AUTOSAR XML (schema 4-2-2)
package /Nexteer/NvMProxy_swc/ComponentTypes
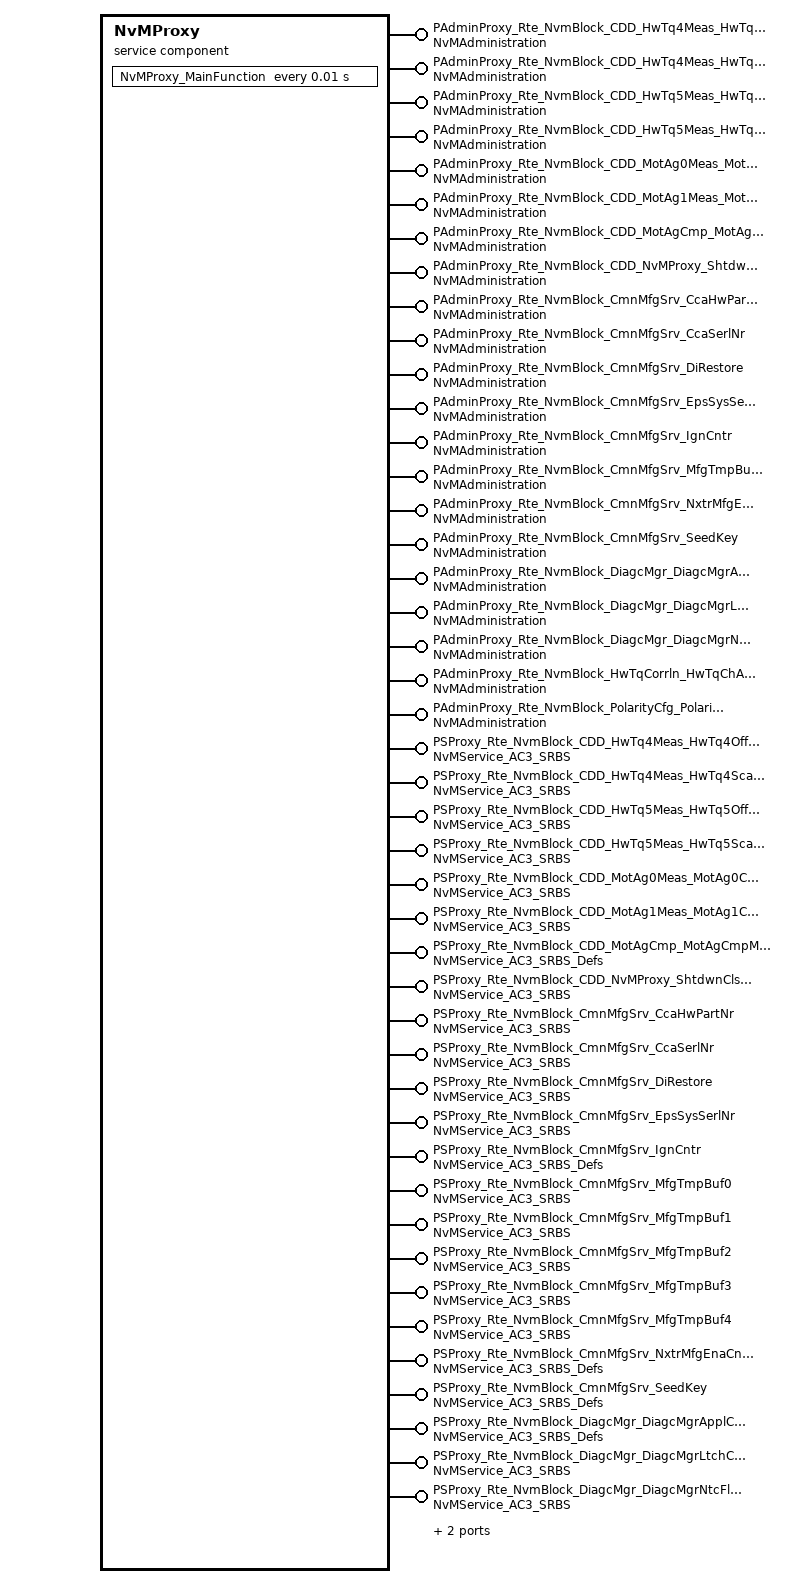
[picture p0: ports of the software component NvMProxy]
  service sw component type NvMProxy
    50 x provide port:
      PAdminProxy_Rte_NvmBlock_CDD_HwTq4Meas_HwTq4Offs_MirrorBlock: server-com-spec{operation=SetBlockProtection, queue-length=1}, provided-interface=NvMAdministration
      PAdminProxy_Rte_NvmBlock_CDD_HwTq4Meas_HwTq4Sca_MirrorBlock: server-com-spec{operation=SetBlockProtection, queue-length=1}, provided-interface=NvMAdministration
      PAdminProxy_Rte_NvmBlock_CDD_HwTq5Meas_HwTq5Offs_MirrorBlock: server-com-spec{operation=SetBlockProtection, queue-length=1}, provided-interface=NvMAdministration
      PAdminProxy_Rte_NvmBlock_CDD_HwTq5Meas_HwTq5Sca_MirrorBlock: server-com-spec{operation=SetBlockProtection, queue-length=1}, provided-interface=NvMAdministration
      PAdminProxy_Rte_NvmBlock_CDD_MotAg0Meas_MotAg0CoeffTbl: server-com-spec{operation=SetBlockProtection, queue-length=1}, provided-interface=NvMAdministration
      PAdminProxy_Rte_NvmBlock_CDD_MotAg1Meas_MotAg1CoeffTbl: server-com-spec{operation=SetBlockProtection, queue-length=1}, provided-interface=NvMAdministration
      PAdminProxy_Rte_NvmBlock_CDD_MotAgCmp_MotAgCmpMotAgBackEmf: server-com-spec{operation=SetBlockProtection, queue-length=1}, provided-interface=NvMAdministration
      PAdminProxy_Rte_NvmBlock_CDD_NvMProxy_ShtdwnClsChk: server-com-spec{operation=SetBlockProtection, queue-length=1}, provided-interface=NvMAdministration
      PAdminProxy_Rte_NvmBlock_CmnMfgSrv_CcaHwPartNr: server-com-spec{operation=SetBlockProtection, queue-length=1}, provided-interface=NvMAdministration
      PAdminProxy_Rte_NvmBlock_CmnMfgSrv_CcaSerlNr: server-com-spec{operation=SetBlockProtection, queue-length=1}, provided-interface=NvMAdministration
      PAdminProxy_Rte_NvmBlock_CmnMfgSrv_DiRestore: server-com-spec{operation=SetBlockProtection, queue-length=1}, provided-interface=NvMAdministration
      PAdminProxy_Rte_NvmBlock_CmnMfgSrv_EpsSysSerlNr: server-com-spec{operation=SetBlockProtection, queue-length=1}, provided-interface=NvMAdministration
      PAdminProxy_Rte_NvmBlock_CmnMfgSrv_IgnCntr: server-com-spec{operation=SetBlockProtection, queue-length=1}, provided-interface=NvMAdministration
      PAdminProxy_Rte_NvmBlock_CmnMfgSrv_MfgTmpBuf{0..4}: server-com-spec{operation=SetBlockProtection, queue-length=1}, provided-interface=NvMAdministration
      PAdminProxy_Rte_NvmBlock_CmnMfgSrv_NxtrMfgEnaCntr: server-com-spec{operation=SetBlockProtection, queue-length=1}, provided-interface=NvMAdministration
      PAdminProxy_Rte_NvmBlock_CmnMfgSrv_SeedKey: server-com-spec{operation=SetBlockProtection, queue-length=1}, provided-interface=NvMAdministration
      PAdminProxy_Rte_NvmBlock_DiagcMgr_DiagcMgrApplCrc: server-com-spec{operation=SetBlockProtection, queue-length=1}, provided-interface=NvMAdministration
      PAdminProxy_Rte_NvmBlock_DiagcMgr_DiagcMgrLtchCntrAry: server-com-spec{operation=SetBlockProtection, queue-length=1}, provided-interface=NvMAdministration
      PAdminProxy_Rte_NvmBlock_DiagcMgr_DiagcMgrNtcFltAry: server-com-spec{operation=SetBlockProtection, queue-length=1}, provided-interface=NvMAdministration
      PAdminProxy_Rte_NvmBlock_HwTqCorrln_HwTqChACmnModCmpLpFilSt: server-com-spec{operation=SetBlockProtection, queue-length=1}, provided-interface=NvMAdministration
      PAdminProxy_Rte_NvmBlock_PolarityCfg_PolarityCfgSaved: server-com-spec{operation=SetBlockProtection, queue-length=1}, provided-interface=NvMAdministration
      PSProxy_Rte_NvmBlock_CDD_HwTq4Meas_HwTq4Offs_MirrorBlock: provided-interface=NvMService_AC3_SRBS
        provided-com-specs:
          operation=EraseBlock, queue-length=1
          operation=GetErrorStatus, queue-length=1
          operation=InvalidateNvBlock, queue-length=1
          operation=ReadBlock, queue-length=1
          operation=SetRamBlockStatus, queue-length=1
          operation=WriteBlock, queue-length=1
      PSProxy_Rte_NvmBlock_CDD_HwTq4Meas_HwTq4Sca_MirrorBlock: provided-interface=NvMService_AC3_SRBS
        provided-com-specs:
          operation=EraseBlock, queue-length=1
          operation=GetErrorStatus, queue-length=1
          operation=InvalidateNvBlock, queue-length=1
          operation=ReadBlock, queue-length=1
          operation=SetRamBlockStatus, queue-length=1
          operation=WriteBlock, queue-length=1
      PSProxy_Rte_NvmBlock_CDD_HwTq5Meas_HwTq5Offs_MirrorBlock: provided-interface=NvMService_AC3_SRBS
        provided-com-specs:
          operation=EraseBlock, queue-length=1
          operation=GetErrorStatus, queue-length=1
          operation=InvalidateNvBlock, queue-length=1
          operation=ReadBlock, queue-length=1
          operation=SetRamBlockStatus, queue-length=1
          operation=WriteBlock, queue-length=1
      PSProxy_Rte_NvmBlock_CDD_HwTq5Meas_HwTq5Sca_MirrorBlock: provided-interface=NvMService_AC3_SRBS
        provided-com-specs:
          operation=EraseBlock, queue-length=1
          operation=GetErrorStatus, queue-length=1
          operation=InvalidateNvBlock, queue-length=1
          operation=ReadBlock, queue-length=1
          operation=SetRamBlockStatus, queue-length=1
          operation=WriteBlock, queue-length=1
      PSProxy_Rte_NvmBlock_CDD_MotAg0Meas_MotAg0CoeffTbl: provided-interface=NvMService_AC3_SRBS
        provided-com-specs:
          operation=EraseBlock, queue-length=1
          operation=GetErrorStatus, queue-length=1
          operation=InvalidateNvBlock, queue-length=1
          operation=ReadBlock, queue-length=1
          operation=SetRamBlockStatus, queue-length=1
          operation=WriteBlock, queue-length=1
      PSProxy_Rte_NvmBlock_CDD_MotAg1Meas_MotAg1CoeffTbl: provided-interface=NvMService_AC3_SRBS
        provided-com-specs:
          operation=EraseBlock, queue-length=1
          operation=GetErrorStatus, queue-length=1
          operation=InvalidateNvBlock, queue-length=1
          operation=ReadBlock, queue-length=1
          operation=SetRamBlockStatus, queue-length=1
          operation=WriteBlock, queue-length=1
      PSProxy_Rte_NvmBlock_CDD_MotAgCmp_MotAgCmpMotAgBackEmf: provided-interface=NvMService_AC3_SRBS_Defs
        provided-com-specs:
          operation=EraseBlock, queue-length=1
          operation=GetErrorStatus, queue-length=1
          operation=InvalidateNvBlock, queue-length=1
          operation=ReadBlock, queue-length=1
          operation=RestoreBlockDefaults, queue-length=1
          operation=SetRamBlockStatus, queue-length=1
          operation=WriteBlock, queue-length=1
      PSProxy_Rte_NvmBlock_CDD_NvMProxy_ShtdwnClsChk: provided-interface=NvMService_AC3_SRBS
        provided-com-specs:
          operation=EraseBlock, queue-length=1
          operation=GetErrorStatus, queue-length=1
          operation=InvalidateNvBlock, queue-length=1
          operation=ReadBlock, queue-length=1
          operation=SetRamBlockStatus, queue-length=1
          operation=WriteBlock, queue-length=1
      PSProxy_Rte_NvmBlock_CmnMfgSrv_CcaHwPartNr: provided-interface=NvMService_AC3_SRBS
        provided-com-specs:
          operation=EraseBlock, queue-length=1
          operation=GetErrorStatus, queue-length=1
          operation=InvalidateNvBlock, queue-length=1
          operation=ReadBlock, queue-length=1
          operation=SetRamBlockStatus, queue-length=1
          operation=WriteBlock, queue-length=1
      PSProxy_Rte_NvmBlock_CmnMfgSrv_CcaSerlNr: provided-interface=NvMService_AC3_SRBS
        provided-com-specs:
          operation=EraseBlock, queue-length=1
          operation=GetErrorStatus, queue-length=1
          operation=InvalidateNvBlock, queue-length=1
          operation=ReadBlock, queue-length=1
          operation=SetRamBlockStatus, queue-length=1
          operation=WriteBlock, queue-length=1
      PSProxy_Rte_NvmBlock_CmnMfgSrv_DiRestore: provided-interface=NvMService_AC3_SRBS
        provided-com-specs:
          operation=EraseBlock, queue-length=1
          operation=GetErrorStatus, queue-length=1
          operation=InvalidateNvBlock, queue-length=1
          operation=ReadBlock, queue-length=1
          operation=SetRamBlockStatus, queue-length=1
          operation=WriteBlock, queue-length=1
      PSProxy_Rte_NvmBlock_CmnMfgSrv_EpsSysSerlNr: provided-interface=NvMService_AC3_SRBS
        provided-com-specs:
          operation=EraseBlock, queue-length=1
          operation=GetErrorStatus, queue-length=1
          operation=InvalidateNvBlock, queue-length=1
          operation=ReadBlock, queue-length=1
          operation=SetRamBlockStatus, queue-length=1
          operation=WriteBlock, queue-length=1
      PSProxy_Rte_NvmBlock_CmnMfgSrv_IgnCntr: provided-interface=NvMService_AC3_SRBS_Defs
        provided-com-specs:
          operation=EraseBlock, queue-length=1
          operation=GetErrorStatus, queue-length=1
          operation=InvalidateNvBlock, queue-length=1
          operation=ReadBlock, queue-length=1
          operation=RestoreBlockDefaults, queue-length=1
          operation=SetRamBlockStatus, queue-length=1
          operation=WriteBlock, queue-length=1
      PSProxy_Rte_NvmBlock_CmnMfgSrv_MfgTmpBuf0: provided-interface=NvMService_AC3_SRBS
        provided-com-specs:
          operation=EraseBlock, queue-length=1
          operation=GetErrorStatus, queue-length=1
          operation=InvalidateNvBlock, queue-length=1
          operation=ReadBlock, queue-length=1
          operation=SetRamBlockStatus, queue-length=1
          operation=WriteBlock, queue-length=1
      PSProxy_Rte_NvmBlock_CmnMfgSrv_MfgTmpBuf1: provided-interface=NvMService_AC3_SRBS
        provided-com-specs:
          operation=EraseBlock, queue-length=1
          operation=GetErrorStatus, queue-length=1
          operation=InvalidateNvBlock, queue-length=1
          operation=ReadBlock, queue-length=1
          operation=SetRamBlockStatus, queue-length=1
          operation=WriteBlock, queue-length=1
      PSProxy_Rte_NvmBlock_CmnMfgSrv_MfgTmpBuf2: provided-interface=NvMService_AC3_SRBS
        provided-com-specs:
          operation=EraseBlock, queue-length=1
          operation=GetErrorStatus, queue-length=1
          operation=InvalidateNvBlock, queue-length=1
          operation=ReadBlock, queue-length=1
          operation=SetRamBlockStatus, queue-length=1
          operation=WriteBlock, queue-length=1
      PSProxy_Rte_NvmBlock_CmnMfgSrv_MfgTmpBuf3: provided-interface=NvMService_AC3_SRBS
        provided-com-specs:
          operation=EraseBlock, queue-length=1
          operation=GetErrorStatus, queue-length=1
          operation=InvalidateNvBlock, queue-length=1
          operation=ReadBlock, queue-length=1
          operation=SetRamBlockStatus, queue-length=1
          operation=WriteBlock, queue-length=1
      PSProxy_Rte_NvmBlock_CmnMfgSrv_MfgTmpBuf4: provided-interface=NvMService_AC3_SRBS
        provided-com-specs:
          operation=EraseBlock, queue-length=1
          operation=GetErrorStatus, queue-length=1
          operation=InvalidateNvBlock, queue-length=1
          operation=ReadBlock, queue-length=1
          operation=SetRamBlockStatus, queue-length=1
          operation=WriteBlock, queue-length=1
      PSProxy_Rte_NvmBlock_CmnMfgSrv_NxtrMfgEnaCntr: provided-interface=NvMService_AC3_SRBS_Defs
        provided-com-specs:
          operation=EraseBlock, queue-length=1
          operation=GetErrorStatus, queue-length=1
          operation=InvalidateNvBlock, queue-length=1
          operation=ReadBlock, queue-length=1
          operation=RestoreBlockDefaults, queue-length=1
          operation=SetRamBlockStatus, queue-length=1
          operation=WriteBlock, queue-length=1
      PSProxy_Rte_NvmBlock_CmnMfgSrv_SeedKey: provided-interface=NvMService_AC3_SRBS_Defs
        provided-com-specs:
          operation=EraseBlock, queue-length=1
          operation=GetErrorStatus, queue-length=1
          operation=InvalidateNvBlock, queue-length=1
          operation=ReadBlock, queue-length=1
          operation=RestoreBlockDefaults, queue-length=1
          operation=SetRamBlockStatus, queue-length=1
          operation=WriteBlock, queue-length=1
      PSProxy_Rte_NvmBlock_DiagcMgr_DiagcMgrApplCrc: provided-interface=NvMService_AC3_SRBS_Defs
        provided-com-specs:
          operation=EraseBlock, queue-length=1
          operation=GetErrorStatus, queue-length=1
          operation=InvalidateNvBlock, queue-length=1
          operation=ReadBlock, queue-length=1
          operation=RestoreBlockDefaults, queue-length=1
          operation=SetRamBlockStatus, queue-length=1
          operation=WriteBlock, queue-length=1
      PSProxy_Rte_NvmBlock_DiagcMgr_DiagcMgrLtchCntrAry: provided-interface=NvMService_AC3_SRBS
        provided-com-specs:
          operation=EraseBlock, queue-length=1
          operation=GetErrorStatus, queue-length=1
          operation=InvalidateNvBlock, queue-length=1
          operation=ReadBlock, queue-length=1
          operation=SetRamBlockStatus, queue-length=1
          operation=WriteBlock, queue-length=1
      PSProxy_Rte_NvmBlock_DiagcMgr_DiagcMgrNtcFltAry: provided-interface=NvMService_AC3_SRBS
        provided-com-specs:
          operation=EraseBlock, queue-length=1
          operation=GetErrorStatus, queue-length=1
          operation=InvalidateNvBlock, queue-length=1
          operation=ReadBlock, queue-length=1
          operation=SetRamBlockStatus, queue-length=1
          operation=WriteBlock, queue-length=1
      PSProxy_Rte_NvmBlock_HwTqCorrln_HwTqChACmnModCmpLpFilSt: provided-interface=NvMService_AC3_SRBS_Defs
        provided-com-specs:
          operation=EraseBlock, queue-length=1
          operation=GetErrorStatus, queue-length=1
          operation=InvalidateNvBlock, queue-length=1
          operation=ReadBlock, queue-length=1
          operation=RestoreBlockDefaults, queue-length=1
          operation=SetRamBlockStatus, queue-length=1
          operation=WriteBlock, queue-length=1
      PSProxy_Rte_NvmBlock_PolarityCfg_PolarityCfgSaved: provided-interface=NvMService_AC3_SRBS_Defs
        provided-com-specs:
          operation=EraseBlock, queue-length=1
          operation=GetErrorStatus, queue-length=1
          operation=InvalidateNvBlock, queue-length=1
          operation=ReadBlock, queue-length=1
          operation=RestoreBlockDefaults, queue-length=1
          operation=SetRamBlockStatus, queue-length=1
          operation=WriteBlock, queue-length=1
    behavior NvMProxyInternalBehavior
      75 x operation invoked event:
        OIT_EraseBlock_PSProxy_Rte_NvmBlock_CDD_HwTq4Meas_HwTq4Offs_MirrorBlock_EraseBlock: start-on-event=EraseBlock, operation=PSProxy_Rte_NvmBlock_CDD_HwTq4Meas_HwTq4Offs_MirrorBlock.EraseBlock
        OIT_EraseBlock_PSProxy_Rte_NvmBlock_CDD_HwTq4Meas_HwTq4Sca_MirrorBlock_EraseBlock: start-on-event=EraseBlock, operation=PSProxy_Rte_NvmBlock_CDD_HwTq4Meas_HwTq4Sca_MirrorBlock.EraseBlock
        OIT_EraseBlock_PSProxy_Rte_NvmBlock_CDD_HwTq5Meas_HwTq5Offs_MirrorBlock_EraseBlock: start-on-event=EraseBlock, operation=PSProxy_Rte_NvmBlock_CDD_HwTq5Meas_HwTq5Offs_MirrorBlock.EraseBlock
        OIT_EraseBlock_PSProxy_Rte_NvmBlock_CDD_HwTq5Meas_HwTq5Sca_MirrorBlock_EraseBlock: start-on-event=EraseBlock, operation=PSProxy_Rte_NvmBlock_CDD_HwTq5Meas_HwTq5Sca_MirrorBlock.EraseBlock
        OIT_EraseBlock_PSProxy_Rte_NvmBlock_CDD_MotAg0Meas_MotAg0CoeffTbl_EraseBlock: start-on-event=EraseBlock, operation=PSProxy_Rte_NvmBlock_CDD_MotAg0Meas_MotAg0CoeffTbl.EraseBlock
        OIT_EraseBlock_PSProxy_Rte_NvmBlock_CDD_MotAg1Meas_MotAg1CoeffTbl_EraseBlock: start-on-event=EraseBlock, operation=PSProxy_Rte_NvmBlock_CDD_MotAg1Meas_MotAg1CoeffTbl.EraseBlock
        OIT_EraseBlock_PSProxy_Rte_NvmBlock_CDD_MotAgCmp_MotAgCmpMotAgBackEmf_EraseBlock: start-on-event=EraseBlock, operation=PSProxy_Rte_NvmBlock_CDD_MotAgCmp_MotAgCmpMotAgBackEmf.EraseBlock
        OIT_EraseBlock_PSProxy_Rte_NvmBlock_CDD_NvMProxy_ShtdwnClsChk_EraseBlock: start-on-event=EraseBlock, operation=PSProxy_Rte_NvmBlock_CDD_NvMProxy_ShtdwnClsChk.EraseBlock
        OIT_EraseBlock_PSProxy_Rte_NvmBlock_CmnMfgSrv_CcaHwPartNr_EraseBlock: start-on-event=EraseBlock, operation=PSProxy_Rte_NvmBlock_CmnMfgSrv_CcaHwPartNr.EraseBlock
        OIT_EraseBlock_PSProxy_Rte_NvmBlock_CmnMfgSrv_CcaSerlNr_EraseBlock: start-on-event=EraseBlock, operation=PSProxy_Rte_NvmBlock_CmnMfgSrv_CcaSerlNr.EraseBlock
        OIT_EraseBlock_PSProxy_Rte_NvmBlock_CmnMfgSrv_DiRestore_EraseBlock: start-on-event=EraseBlock, operation=PSProxy_Rte_NvmBlock_CmnMfgSrv_DiRestore.EraseBlock
        OIT_EraseBlock_PSProxy_Rte_NvmBlock_CmnMfgSrv_EpsSysSerlNr_EraseBlock: start-on-event=EraseBlock, operation=PSProxy_Rte_NvmBlock_CmnMfgSrv_EpsSysSerlNr.EraseBlock
        OIT_EraseBlock_PSProxy_Rte_NvmBlock_CmnMfgSrv_IgnCntr_EraseBlock: start-on-event=EraseBlock, operation=PSProxy_Rte_NvmBlock_CmnMfgSrv_IgnCntr.EraseBlock
        OIT_EraseBlock_PSProxy_Rte_NvmBlock_CmnMfgSrv_MfgTmpBuf{0..4}_EraseBlock: start-on-event=EraseBlock, operation=PSProxy_Rte_NvmBlock_CmnMfgSrv_MfgTmpBuf{0..4}.EraseBlock
        OIT_EraseBlock_PSProxy_Rte_NvmBlock_CmnMfgSrv_NxtrMfgEnaCntr_EraseBlock: start-on-event=EraseBlock, operation=PSProxy_Rte_NvmBlock_CmnMfgSrv_NxtrMfgEnaCntr.EraseBlock
        OIT_EraseBlock_PSProxy_Rte_NvmBlock_CmnMfgSrv_SeedKey_EraseBlock: start-on-event=EraseBlock, operation=PSProxy_Rte_NvmBlock_CmnMfgSrv_SeedKey.EraseBlock
        OIT_EraseBlock_PSProxy_Rte_NvmBlock_DiagcMgr_DiagcMgrApplCrc_EraseBlock: start-on-event=EraseBlock, operation=PSProxy_Rte_NvmBlock_DiagcMgr_DiagcMgrApplCrc.EraseBlock
        OIT_EraseBlock_PSProxy_Rte_NvmBlock_DiagcMgr_DiagcMgrLtchCntrAry_EraseBlock: start-on-event=EraseBlock, operation=PSProxy_Rte_NvmBlock_DiagcMgr_DiagcMgrLtchCntrAry.EraseBlock
        OIT_EraseBlock_PSProxy_Rte_NvmBlock_DiagcMgr_DiagcMgrNtcFltAry_EraseBlock: start-on-event=EraseBlock, operation=PSProxy_Rte_NvmBlock_DiagcMgr_DiagcMgrNtcFltAry.EraseBlock
        OIT_EraseBlock_PSProxy_Rte_NvmBlock_HwTqCorrln_HwTqChACmnModCmpLpFilSt_EraseBlock: start-on-event=EraseBlock, operation=PSProxy_Rte_NvmBlock_HwTqCorrln_HwTqChACmnModCmpLpFilSt.EraseBlock
        OIT_EraseBlock_PSProxy_Rte_NvmBlock_PolarityCfg_PolarityCfgSaved_EraseBlock: start-on-event=EraseBlock, operation=PSProxy_Rte_NvmBlock_PolarityCfg_PolarityCfgSaved.EraseBlock
        OIT_GetErrorStatus_PSProxy_Rte_NvmBlock_CDD_HwTq4Meas_HwTq4Offs_MirrorBlock_GetErrorStatus: start-on-event=GetErrorStatus, operation=PSProxy_Rte_NvmBlock_CDD_HwTq4Meas_HwTq4Offs_MirrorBlock.GetErrorStatus
        OIT_GetErrorStatus_PSProxy_Rte_NvmBlock_CDD_HwTq4Meas_HwTq4Sca_MirrorBlock_GetErrorStatus: start-on-event=GetErrorStatus, operation=PSProxy_Rte_NvmBlock_CDD_HwTq4Meas_HwTq4Sca_MirrorBlock.GetErrorStatus
        OIT_GetErrorStatus_PSProxy_Rte_NvmBlock_CDD_HwTq5Meas_HwTq5Offs_MirrorBlock_GetErrorStatus: start-on-event=GetErrorStatus, operation=PSProxy_Rte_NvmBlock_CDD_HwTq5Meas_HwTq5Offs_MirrorBlock.GetErrorStatus
        OIT_GetErrorStatus_PSProxy_Rte_NvmBlock_CDD_HwTq5Meas_HwTq5Sca_MirrorBlock_GetErrorStatus: start-on-event=GetErrorStatus, operation=PSProxy_Rte_NvmBlock_CDD_HwTq5Meas_HwTq5Sca_MirrorBlock.GetErrorStatus
        OIT_GetErrorStatus_PSProxy_Rte_NvmBlock_CDD_MotAg0Meas_MotAg0CoeffTbl_GetErrorStatus: start-on-event=GetErrorStatus, operation=PSProxy_Rte_NvmBlock_CDD_MotAg0Meas_MotAg0CoeffTbl.GetErrorStatus
        OIT_GetErrorStatus_PSProxy_Rte_NvmBlock_CDD_MotAg1Meas_MotAg1CoeffTbl_GetErrorStatus: start-on-event=GetErrorStatus, operation=PSProxy_Rte_NvmBlock_CDD_MotAg1Meas_MotAg1CoeffTbl.GetErrorStatus
        OIT_GetErrorStatus_PSProxy_Rte_NvmBlock_CDD_MotAgCmp_MotAgCmpMotAgBackEmf_GetErrorStatus: start-on-event=GetErrorStatus, operation=PSProxy_Rte_NvmBlock_CDD_MotAgCmp_MotAgCmpMotAgBackEmf.GetErrorStatus
        OIT_GetErrorStatus_PSProxy_Rte_NvmBlock_CDD_NvMProxy_ShtdwnClsChk_GetErrorStatus: start-on-event=GetErrorStatus, operation=PSProxy_Rte_NvmBlock_CDD_NvMProxy_ShtdwnClsChk.GetErrorStatus
        OIT_GetErrorStatus_PSProxy_Rte_NvmBlock_CmnMfgSrv_CcaHwPartNr_GetErrorStatus: start-on-event=GetErrorStatus, operation=PSProxy_Rte_NvmBlock_CmnMfgSrv_CcaHwPartNr.GetErrorStatus
        OIT_GetErrorStatus_PSProxy_Rte_NvmBlock_CmnMfgSrv_CcaSerlNr_GetErrorStatus: start-on-event=GetErrorStatus, operation=PSProxy_Rte_NvmBlock_CmnMfgSrv_CcaSerlNr.GetErrorStatus
        OIT_GetErrorStatus_PSProxy_Rte_NvmBlock_CmnMfgSrv_DiRestore_GetErrorStatus: start-on-event=GetErrorStatus, operation=PSProxy_Rte_NvmBlock_CmnMfgSrv_DiRestore.GetErrorStatus
        OIT_GetErrorStatus_PSProxy_Rte_NvmBlock_CmnMfgSrv_EpsSysSerlNr_GetErrorStatus: start-on-event=GetErrorStatus, operation=PSProxy_Rte_NvmBlock_CmnMfgSrv_EpsSysSerlNr.GetErrorStatus
        OIT_GetErrorStatus_PSProxy_Rte_NvmBlock_CmnMfgSrv_IgnCntr_GetErrorStatus: start-on-event=GetErrorStatus, operation=PSProxy_Rte_NvmBlock_CmnMfgSrv_IgnCntr.GetErrorStatus
        OIT_GetErrorStatus_PSProxy_Rte_NvmBlock_CmnMfgSrv_MfgTmpBuf{0..4}_GetErrorStatus: start-on-event=GetErrorStatus, operation=PSProxy_Rte_NvmBlock_CmnMfgSrv_MfgTmpBuf{0..4}.GetErrorStatus
        OIT_GetErrorStatus_PSProxy_Rte_NvmBlock_CmnMfgSrv_NxtrMfgEnaCntr_GetErrorStatus: start-on-event=GetErrorStatus, operation=PSProxy_Rte_NvmBlock_CmnMfgSrv_NxtrMfgEnaCntr.GetErrorStatus
        OIT_GetErrorStatus_PSProxy_Rte_NvmBlock_CmnMfgSrv_SeedKey_GetErrorStatus: start-on-event=GetErrorStatus, operation=PSProxy_Rte_NvmBlock_CmnMfgSrv_SeedKey.GetErrorStatus
        OIT_GetErrorStatus_PSProxy_Rte_NvmBlock_DiagcMgr_DiagcMgrApplCrc_GetErrorStatus: start-on-event=GetErrorStatus, operation=PSProxy_Rte_NvmBlock_DiagcMgr_DiagcMgrApplCrc.GetErrorStatus
        OIT_GetErrorStatus_PSProxy_Rte_NvmBlock_DiagcMgr_DiagcMgrLtchCntrAry_GetErrorStatus: start-on-event=GetErrorStatus, operation=PSProxy_Rte_NvmBlock_DiagcMgr_DiagcMgrLtchCntrAry.GetErrorStatus
        OIT_GetErrorStatus_PSProxy_Rte_NvmBlock_DiagcMgr_DiagcMgrNtcFltAry_GetErrorStatus: start-on-event=GetErrorStatus, operation=PSProxy_Rte_NvmBlock_DiagcMgr_DiagcMgrNtcFltAry.GetErrorStatus
        OIT_GetErrorStatus_PSProxy_Rte_NvmBlock_HwTqCorrln_HwTqChACmnModCmpLpFilSt_GetErrorStatus: start-on-event=GetErrorStatus, operation=PSProxy_Rte_NvmBlock_HwTqCorrln_HwTqChACmnModCmpLpFilSt.GetErrorStatus
        OIT_GetErrorStatus_PSProxy_Rte_NvmBlock_PolarityCfg_PolarityCfgSaved_GetErrorStatus: start-on-event=GetErrorStatus, operation=PSProxy_Rte_NvmBlock_PolarityCfg_PolarityCfgSaved.GetErrorStatus
        OIT_InvalidateNvBlock_PSProxy_Rte_NvmBlock_CDD_HwTq4Meas_HwTq4Offs_MirrorBlock_InvalidateNvBlock: start-on-event=InvalidateNvBlock, operation=PSProxy_Rte_NvmBlock_CDD_HwTq4Meas_HwTq4Offs_MirrorBlock.InvalidateNvBlock
        OIT_InvalidateNvBlock_PSProxy_Rte_NvmBlock_CDD_HwTq4Meas_HwTq4Sca_MirrorBlock_InvalidateNvBlock: start-on-event=InvalidateNvBlock, operation=PSProxy_Rte_NvmBlock_CDD_HwTq4Meas_HwTq4Sca_MirrorBlock.InvalidateNvBlock
        OIT_InvalidateNvBlock_PSProxy_Rte_NvmBlock_CDD_HwTq5Meas_HwTq5Offs_MirrorBlock_InvalidateNvBlock: start-on-event=InvalidateNvBlock, operation=PSProxy_Rte_NvmBlock_CDD_HwTq5Meas_HwTq5Offs_MirrorBlock.InvalidateNvBlock
        OIT_InvalidateNvBlock_PSProxy_Rte_NvmBlock_CDD_HwTq5Meas_HwTq5Sca_MirrorBlock_InvalidateNvBlock: start-on-event=InvalidateNvBlock, operation=PSProxy_Rte_NvmBlock_CDD_HwTq5Meas_HwTq5Sca_MirrorBlock.InvalidateNvBlock
        OIT_InvalidateNvBlock_PSProxy_Rte_NvmBlock_CDD_MotAg0Meas_MotAg0CoeffTbl_InvalidateNvBlock: start-on-event=InvalidateNvBlock, operation=PSProxy_Rte_NvmBlock_CDD_MotAg0Meas_MotAg0CoeffTbl.InvalidateNvBlock
        OIT_InvalidateNvBlock_PSProxy_Rte_NvmBlock_CDD_MotAg1Meas_MotAg1CoeffTbl_InvalidateNvBlock: start-on-event=InvalidateNvBlock, operation=PSProxy_Rte_NvmBlock_CDD_MotAg1Meas_MotAg1CoeffTbl.InvalidateNvBlock
        OIT_InvalidateNvBlock_PSProxy_Rte_NvmBlock_CDD_MotAgCmp_MotAgCmpMotAgBackEmf_InvalidateNvBlock: start-on-event=InvalidateNvBlock, operation=PSProxy_Rte_NvmBlock_CDD_MotAgCmp_MotAgCmpMotAgBackEmf.InvalidateNvBlock
        OIT_InvalidateNvBlock_PSProxy_Rte_NvmBlock_CDD_NvMProxy_ShtdwnClsChk_InvalidateNvBlock: start-on-event=InvalidateNvBlock, operation=PSProxy_Rte_NvmBlock_CDD_NvMProxy_ShtdwnClsChk.InvalidateNvBlock
        OIT_InvalidateNvBlock_PSProxy_Rte_NvmBlock_CmnMfgSrv_CcaHwPartNr_InvalidateNvBlock: start-on-event=InvalidateNvBlock, operation=PSProxy_Rte_NvmBlock_CmnMfgSrv_CcaHwPartNr.InvalidateNvBlock
        OIT_InvalidateNvBlock_PSProxy_Rte_NvmBlock_CmnMfgSrv_CcaSerlNr_InvalidateNvBlock: start-on-event=InvalidateNvBlock, operation=PSProxy_Rte_NvmBlock_CmnMfgSrv_CcaSerlNr.InvalidateNvBlock
        OIT_InvalidateNvBlock_PSProxy_Rte_NvmBlock_CmnMfgSrv_DiRestore_InvalidateNvBlock: start-on-event=InvalidateNvBlock, operation=PSProxy_Rte_NvmBlock_CmnMfgSrv_DiRestore.InvalidateNvBlock
        OIT_InvalidateNvBlock_PSProxy_Rte_NvmBlock_CmnMfgSrv_EpsSysSerlNr_InvalidateNvBlock: start-on-event=InvalidateNvBlock, operation=PSProxy_Rte_NvmBlock_CmnMfgSrv_EpsSysSerlNr.InvalidateNvBlock
        OIT_InvalidateNvBlock_PSProxy_Rte_NvmBlock_CmnMfgSrv_IgnCntr_InvalidateNvBlock: start-on-event=InvalidateNvBlock, operation=PSProxy_Rte_NvmBlock_CmnMfgSrv_IgnCntr.InvalidateNvBlock
        OIT_InvalidateNvBlock_PSProxy_Rte_NvmBlock_CmnMfgSrv_MfgTmpBuf{0..4}_InvalidateNvBlock: start-on-event=InvalidateNvBlock, operation=PSProxy_Rte_NvmBlock_CmnMfgSrv_MfgTmpBuf{0..4}.InvalidateNvBlock
        OIT_InvalidateNvBlock_PSProxy_Rte_NvmBlock_CmnMfgSrv_NxtrMfgEnaCntr_InvalidateNvBlock: start-on-event=InvalidateNvBlock, operation=PSProxy_Rte_NvmBlock_CmnMfgSrv_NxtrMfgEnaCntr.InvalidateNvBlock
        OIT_InvalidateNvBlock_PSProxy_Rte_NvmBlock_CmnMfgSrv_SeedKey_InvalidateNvBlock: start-on-event=InvalidateNvBlock, operation=PSProxy_Rte_NvmBlock_CmnMfgSrv_SeedKey.InvalidateNvBlock
        OIT_InvalidateNvBlock_PSProxy_Rte_NvmBlock_DiagcMgr_DiagcMgrApplCrc_InvalidateNvBlock: start-on-event=InvalidateNvBlock, operation=PSProxy_Rte_NvmBlock_DiagcMgr_DiagcMgrApplCrc.InvalidateNvBlock
        OIT_InvalidateNvBlock_PSProxy_Rte_NvmBlock_DiagcMgr_DiagcMgrLtchCntrAry_InvalidateNvBlock: start-on-event=InvalidateNvBlock, operation=PSProxy_Rte_NvmBlock_DiagcMgr_DiagcMgrLtchCntrAry.InvalidateNvBlock
        OIT_InvalidateNvBlock_PSProxy_Rte_NvmBlock_DiagcMgr_DiagcMgrNtcFltAry_InvalidateNvBlock: start-on-event=InvalidateNvBlock, operation=PSProxy_Rte_NvmBlock_DiagcMgr_DiagcMgrNtcFltAry.InvalidateNvBlock
        OIT_InvalidateNvBlock_PSProxy_Rte_NvmBlock_HwTqCorrln_HwTqChACmnModCmpLpFilSt_InvalidateNvBlock: start-on-event=InvalidateNvBlock, operation=PSProxy_Rte_NvmBlock_HwTqCorrln_HwTqChACmnModCmpLpFilSt.InvalidateNvBlock
        OIT_InvalidateNvBlock_PSProxy_Rte_NvmBlock_PolarityCfg_PolarityCfgSaved_InvalidateNvBlock: start-on-event=InvalidateNvBlock, operation=PSProxy_Rte_NvmBlock_PolarityCfg_PolarityCfgSaved.InvalidateNvBlock
      timing event Timer_NvMProxy_MainFunction: start-on-event=NvMProxy_MainFunction, period=0.01
      107 x operation invoked event:
        OIT_ReadBlock_PSProxy_Rte_NvmBlock_CDD_HwTq4Meas_HwTq4Offs_MirrorBlock_ReadBlock: start-on-event=ReadBlock, operation=PSProxy_Rte_NvmBlock_CDD_HwTq4Meas_HwTq4Offs_MirrorBlock.ReadBlock
        OIT_ReadBlock_PSProxy_Rte_NvmBlock_CDD_HwTq4Meas_HwTq4Sca_MirrorBlock_ReadBlock: start-on-event=ReadBlock, operation=PSProxy_Rte_NvmBlock_CDD_HwTq4Meas_HwTq4Sca_MirrorBlock.ReadBlock
        OIT_ReadBlock_PSProxy_Rte_NvmBlock_CDD_HwTq5Meas_HwTq5Offs_MirrorBlock_ReadBlock: start-on-event=ReadBlock, operation=PSProxy_Rte_NvmBlock_CDD_HwTq5Meas_HwTq5Offs_MirrorBlock.ReadBlock
        OIT_ReadBlock_PSProxy_Rte_NvmBlock_CDD_HwTq5Meas_HwTq5Sca_MirrorBlock_ReadBlock: start-on-event=ReadBlock, operation=PSProxy_Rte_NvmBlock_CDD_HwTq5Meas_HwTq5Sca_MirrorBlock.ReadBlock
        OIT_ReadBlock_PSProxy_Rte_NvmBlock_CDD_MotAg0Meas_MotAg0CoeffTbl_ReadBlock: start-on-event=ReadBlock, operation=PSProxy_Rte_NvmBlock_CDD_MotAg0Meas_MotAg0CoeffTbl.ReadBlock
        OIT_ReadBlock_PSProxy_Rte_NvmBlock_CDD_MotAg1Meas_MotAg1CoeffTbl_ReadBlock: start-on-event=ReadBlock, operation=PSProxy_Rte_NvmBlock_CDD_MotAg1Meas_MotAg1CoeffTbl.ReadBlock
        OIT_ReadBlock_PSProxy_Rte_NvmBlock_CDD_MotAgCmp_MotAgCmpMotAgBackEmf_ReadBlock: start-on-event=ReadBlock, operation=PSProxy_Rte_NvmBlock_CDD_MotAgCmp_MotAgCmpMotAgBackEmf.ReadBlock
        OIT_ReadBlock_PSProxy_Rte_NvmBlock_CDD_NvMProxy_ShtdwnClsChk_ReadBlock: start-on-event=ReadBlock, operation=PSProxy_Rte_NvmBlock_CDD_NvMProxy_ShtdwnClsChk.ReadBlock
        OIT_ReadBlock_PSProxy_Rte_NvmBlock_CmnMfgSrv_CcaHwPartNr_ReadBlock: start-on-event=ReadBlock, operation=PSProxy_Rte_NvmBlock_CmnMfgSrv_CcaHwPartNr.ReadBlock
        OIT_ReadBlock_PSProxy_Rte_NvmBlock_CmnMfgSrv_CcaSerlNr_ReadBlock: start-on-event=ReadBlock, operation=PSProxy_Rte_NvmBlock_CmnMfgSrv_CcaSerlNr.ReadBlock
        OIT_ReadBlock_PSProxy_Rte_NvmBlock_CmnMfgSrv_DiRestore_ReadBlock: start-on-event=ReadBlock, operation=PSProxy_Rte_NvmBlock_CmnMfgSrv_DiRestore.ReadBlock
        OIT_ReadBlock_PSProxy_Rte_NvmBlock_CmnMfgSrv_EpsSysSerlNr_ReadBlock: start-on-event=ReadBlock, operation=PSProxy_Rte_NvmBlock_CmnMfgSrv_EpsSysSerlNr.ReadBlock
        OIT_ReadBlock_PSProxy_Rte_NvmBlock_CmnMfgSrv_IgnCntr_ReadBlock: start-on-event=ReadBlock, operation=PSProxy_Rte_NvmBlock_CmnMfgSrv_IgnCntr.ReadBlock
        OIT_ReadBlock_PSProxy_Rte_NvmBlock_CmnMfgSrv_MfgTmpBuf{0..4}_ReadBlock: start-on-event=ReadBlock, operation=PSProxy_Rte_NvmBlock_CmnMfgSrv_MfgTmpBuf{0..4}.ReadBlock
        OIT_ReadBlock_PSProxy_Rte_NvmBlock_CmnMfgSrv_NxtrMfgEnaCntr_ReadBlock: start-on-event=ReadBlock, operation=PSProxy_Rte_NvmBlock_CmnMfgSrv_NxtrMfgEnaCntr.ReadBlock
        OIT_ReadBlock_PSProxy_Rte_NvmBlock_CmnMfgSrv_SeedKey_ReadBlock: start-on-event=ReadBlock, operation=PSProxy_Rte_NvmBlock_CmnMfgSrv_SeedKey.ReadBlock
        OIT_ReadBlock_PSProxy_Rte_NvmBlock_DiagcMgr_DiagcMgrApplCrc_ReadBlock: start-on-event=ReadBlock, operation=PSProxy_Rte_NvmBlock_DiagcMgr_DiagcMgrApplCrc.ReadBlock
        OIT_ReadBlock_PSProxy_Rte_NvmBlock_DiagcMgr_DiagcMgrLtchCntrAry_ReadBlock: start-on-event=ReadBlock, operation=PSProxy_Rte_NvmBlock_DiagcMgr_DiagcMgrLtchCntrAry.ReadBlock
        OIT_ReadBlock_PSProxy_Rte_NvmBlock_DiagcMgr_DiagcMgrNtcFltAry_ReadBlock: start-on-event=ReadBlock, operation=PSProxy_Rte_NvmBlock_DiagcMgr_DiagcMgrNtcFltAry.ReadBlock
        OIT_ReadBlock_PSProxy_Rte_NvmBlock_HwTqCorrln_HwTqChACmnModCmpLpFilSt_ReadBlock: start-on-event=ReadBlock, operation=PSProxy_Rte_NvmBlock_HwTqCorrln_HwTqChACmnModCmpLpFilSt.ReadBlock
        OIT_ReadBlock_PSProxy_Rte_NvmBlock_PolarityCfg_PolarityCfgSaved_ReadBlock: start-on-event=ReadBlock, operation=PSProxy_Rte_NvmBlock_PolarityCfg_PolarityCfgSaved.ReadBlock
        OIT_RestoreBlockDefaults_PSProxy_Rte_NvmBlock_CDD_MotAgCmp_MotAgCmpMotAgBackEmf_RestoreBlockDefaults: start-on-event=RestoreBlockDefaults, operation=PSProxy_Rte_NvmBlock_CDD_MotAgCmp_MotAgCmpMotAgBackEmf.RestoreBlockDefaults
        OIT_RestoreBlockDefaults_PSProxy_Rte_NvmBlock_CmnMfgSrv_IgnCntr_RestoreBlockDefaults: start-on-event=RestoreBlockDefaults, operation=PSProxy_Rte_NvmBlock_CmnMfgSrv_IgnCntr.RestoreBlockDefaults
        OIT_RestoreBlockDefaults_PSProxy_Rte_NvmBlock_CmnMfgSrv_NxtrMfgEnaCntr_RestoreBlockDefaults: start-on-event=RestoreBlockDefaults, operation=PSProxy_Rte_NvmBlock_CmnMfgSrv_NxtrMfgEnaCntr.RestoreBlockDefaults
        OIT_RestoreBlockDefaults_PSProxy_Rte_NvmBlock_CmnMfgSrv_SeedKey_RestoreBlockDefaults: start-on-event=RestoreBlockDefaults, operation=PSProxy_Rte_NvmBlock_CmnMfgSrv_SeedKey.RestoreBlockDefaults
        OIT_RestoreBlockDefaults_PSProxy_Rte_NvmBlock_DiagcMgr_DiagcMgrApplCrc_RestoreBlockDefaults: start-on-event=RestoreBlockDefaults, operation=PSProxy_Rte_NvmBlock_DiagcMgr_DiagcMgrApplCrc.RestoreBlockDefaults
        OIT_RestoreBlockDefaults_PSProxy_Rte_NvmBlock_HwTqCorrln_HwTqChACmnModCmpLpFilSt_RestoreBlockDefaults: start-on-event=RestoreBlockDefaults, operation=PSProxy_Rte_NvmBlock_HwTqCorrln_HwTqChACmnModCmpLpFilSt.RestoreBlockDefaults
        OIT_RestoreBlockDefaults_PSProxy_Rte_NvmBlock_PolarityCfg_PolarityCfgSaved_RestoreBlockDefaults: start-on-event=RestoreBlockDefaults, operation=PSProxy_Rte_NvmBlock_PolarityCfg_PolarityCfgSaved.RestoreBlockDefaults
        OIT_SetBlockProtection_PAdminProxy_Rte_NvmBlock_CDD_HwTq4Meas_HwTq4Offs_MirrorBlock_SetBlockProtection: start-on-event=SetBlockProtection, operation=PAdminProxy_Rte_NvmBlock_CDD_HwTq4Meas_HwTq4Offs_MirrorBlock.SetBlockProtection
        OIT_SetBlockProtection_PAdminProxy_Rte_NvmBlock_CDD_HwTq4Meas_HwTq4Sca_MirrorBlock_SetBlockProtection: start-on-event=SetBlockProtection, operation=PAdminProxy_Rte_NvmBlock_CDD_HwTq4Meas_HwTq4Sca_MirrorBlock.SetBlockProtection
        OIT_SetBlockProtection_PAdminProxy_Rte_NvmBlock_CDD_HwTq5Meas_HwTq5Offs_MirrorBlock_SetBlockProtection: start-on-event=SetBlockProtection, operation=PAdminProxy_Rte_NvmBlock_CDD_HwTq5Meas_HwTq5Offs_MirrorBlock.SetBlockProtection
        OIT_SetBlockProtection_PAdminProxy_Rte_NvmBlock_CDD_HwTq5Meas_HwTq5Sca_MirrorBlock_SetBlockProtection: start-on-event=SetBlockProtection, operation=PAdminProxy_Rte_NvmBlock_CDD_HwTq5Meas_HwTq5Sca_MirrorBlock.SetBlockProtection
        OIT_SetBlockProtection_PAdminProxy_Rte_NvmBlock_CDD_MotAg0Meas_MotAg0CoeffTbl_SetBlockProtection: start-on-event=SetBlockProtection, operation=PAdminProxy_Rte_NvmBlock_CDD_MotAg0Meas_MotAg0CoeffTbl.SetBlockProtection
        OIT_SetBlockProtection_PAdminProxy_Rte_NvmBlock_CDD_MotAg1Meas_MotAg1CoeffTbl_SetBlockProtection: start-on-event=SetBlockProtection, operation=PAdminProxy_Rte_NvmBlock_CDD_MotAg1Meas_MotAg1CoeffTbl.SetBlockProtection
        OIT_SetBlockProtection_PAdminProxy_Rte_NvmBlock_CDD_MotAgCmp_MotAgCmpMotAgBackEmf_SetBlockProtection: start-on-event=SetBlockProtection, operation=PAdminProxy_Rte_NvmBlock_CDD_MotAgCmp_MotAgCmpMotAgBackEmf.SetBlockProtection
        OIT_SetBlockProtection_PAdminProxy_Rte_NvmBlock_CDD_NvMProxy_ShtdwnClsChk_SetBlockProtection: start-on-event=SetBlockProtection, operation=PAdminProxy_Rte_NvmBlock_CDD_NvMProxy_ShtdwnClsChk.SetBlockProtection
        OIT_SetBlockProtection_PAdminProxy_Rte_NvmBlock_CmnMfgSrv_CcaHwPartNr_SetBlockProtection: start-on-event=SetBlockProtection, operation=PAdminProxy_Rte_NvmBlock_CmnMfgSrv_CcaHwPartNr.SetBlockProtection
        OIT_SetBlockProtection_PAdminProxy_Rte_NvmBlock_CmnMfgSrv_CcaSerlNr_SetBlockProtection: start-on-event=SetBlockProtection, operation=PAdminProxy_Rte_NvmBlock_CmnMfgSrv_CcaSerlNr.SetBlockProtection
        OIT_SetBlockProtection_PAdminProxy_Rte_NvmBlock_CmnMfgSrv_DiRestore_SetBlockProtection: start-on-event=SetBlockProtection, operation=PAdminProxy_Rte_NvmBlock_CmnMfgSrv_DiRestore.SetBlockProtection
        OIT_SetBlockProtection_PAdminProxy_Rte_NvmBlock_CmnMfgSrv_EpsSysSerlNr_SetBlockProtection: start-on-event=SetBlockProtection, operation=PAdminProxy_Rte_NvmBlock_CmnMfgSrv_EpsSysSerlNr.SetBlockProtection
        OIT_SetBlockProtection_PAdminProxy_Rte_NvmBlock_CmnMfgSrv_IgnCntr_SetBlockProtection: start-on-event=SetBlockProtection, operation=PAdminProxy_Rte_NvmBlock_CmnMfgSrv_IgnCntr.SetBlockProtection
        OIT_SetBlockProtection_PAdminProxy_Rte_NvmBlock_CmnMfgSrv_MfgTmpBuf{0..4}_SetBlockProtection: start-on-event=SetBlockProtection, operation=PAdminProxy_Rte_NvmBlock_CmnMfgSrv_MfgTmpBuf{0..4}.SetBlockProtection
        OIT_SetBlockProtection_PAdminProxy_Rte_NvmBlock_CmnMfgSrv_NxtrMfgEnaCntr_SetBlockProtection: start-on-event=SetBlockProtection, operation=PAdminProxy_Rte_NvmBlock_CmnMfgSrv_NxtrMfgEnaCntr.SetBlockProtection
        OIT_SetBlockProtection_PAdminProxy_Rte_NvmBlock_CmnMfgSrv_SeedKey_SetBlockProtection: start-on-event=SetBlockProtection, operation=PAdminProxy_Rte_NvmBlock_CmnMfgSrv_SeedKey.SetBlockProtection
        OIT_SetBlockProtection_PAdminProxy_Rte_NvmBlock_DiagcMgr_DiagcMgrApplCrc_SetBlockProtection: start-on-event=SetBlockProtection, operation=PAdminProxy_Rte_NvmBlock_DiagcMgr_DiagcMgrApplCrc.SetBlockProtection
        OIT_SetBlockProtection_PAdminProxy_Rte_NvmBlock_DiagcMgr_DiagcMgrLtchCntrAry_SetBlockProtection: start-on-event=SetBlockProtection, operation=PAdminProxy_Rte_NvmBlock_DiagcMgr_DiagcMgrLtchCntrAry.SetBlockProtection
        OIT_SetBlockProtection_PAdminProxy_Rte_NvmBlock_DiagcMgr_DiagcMgrNtcFltAry_SetBlockProtection: start-on-event=SetBlockProtection, operation=PAdminProxy_Rte_NvmBlock_DiagcMgr_DiagcMgrNtcFltAry.SetBlockProtection
        OIT_SetBlockProtection_PAdminProxy_Rte_NvmBlock_HwTqCorrln_HwTqChACmnModCmpLpFilSt_SetBlockProtection: start-on-event=SetBlockProtection, operation=PAdminProxy_Rte_NvmBlock_HwTqCorrln_HwTqChACmnModCmpLpFilSt.SetBlockProtection
        OIT_SetBlockProtection_PAdminProxy_Rte_NvmBlock_PolarityCfg_PolarityCfgSaved_SetBlockProtection: start-on-event=SetBlockProtection, operation=PAdminProxy_Rte_NvmBlock_PolarityCfg_PolarityCfgSaved.SetBlockProtection
        OIT_SetRamBlockStatus_PSProxy_Rte_NvmBlock_CDD_HwTq4Meas_HwTq4Offs_MirrorBlock_SetRamBlockStatus: start-on-event=SetRamBlockStatus, operation=PSProxy_Rte_NvmBlock_CDD_HwTq4Meas_HwTq4Offs_MirrorBlock.SetRamBlockStatus
        OIT_SetRamBlockStatus_PSProxy_Rte_NvmBlock_CDD_HwTq4Meas_HwTq4Sca_MirrorBlock_SetRamBlockStatus: start-on-event=SetRamBlockStatus, operation=PSProxy_Rte_NvmBlock_CDD_HwTq4Meas_HwTq4Sca_MirrorBlock.SetRamBlockStatus
        OIT_SetRamBlockStatus_PSProxy_Rte_NvmBlock_CDD_HwTq5Meas_HwTq5Offs_MirrorBlock_SetRamBlockStatus: start-on-event=SetRamBlockStatus, operation=PSProxy_Rte_NvmBlock_CDD_HwTq5Meas_HwTq5Offs_MirrorBlock.SetRamBlockStatus
        OIT_SetRamBlockStatus_PSProxy_Rte_NvmBlock_CDD_HwTq5Meas_HwTq5Sca_MirrorBlock_SetRamBlockStatus: start-on-event=SetRamBlockStatus, operation=PSProxy_Rte_NvmBlock_CDD_HwTq5Meas_HwTq5Sca_MirrorBlock.SetRamBlockStatus
        OIT_SetRamBlockStatus_PSProxy_Rte_NvmBlock_CDD_MotAg0Meas_MotAg0CoeffTbl_SetRamBlockStatus: start-on-event=SetRamBlockStatus, operation=PSProxy_Rte_NvmBlock_CDD_MotAg0Meas_MotAg0CoeffTbl.SetRamBlockStatus
        OIT_SetRamBlockStatus_PSProxy_Rte_NvmBlock_CDD_MotAg1Meas_MotAg1CoeffTbl_SetRamBlockStatus: start-on-event=SetRamBlockStatus, operation=PSProxy_Rte_NvmBlock_CDD_MotAg1Meas_MotAg1CoeffTbl.SetRamBlockStatus
        OIT_SetRamBlockStatus_PSProxy_Rte_NvmBlock_CDD_MotAgCmp_MotAgCmpMotAgBackEmf_SetRamBlockStatus: start-on-event=SetRamBlockStatus, operation=PSProxy_Rte_NvmBlock_CDD_MotAgCmp_MotAgCmpMotAgBackEmf.SetRamBlockStatus
        OIT_SetRamBlockStatus_PSProxy_Rte_NvmBlock_CDD_NvMProxy_ShtdwnClsChk_SetRamBlockStatus: start-on-event=SetRamBlockStatus, operation=PSProxy_Rte_NvmBlock_CDD_NvMProxy_ShtdwnClsChk.SetRamBlockStatus
        OIT_SetRamBlockStatus_PSProxy_Rte_NvmBlock_CmnMfgSrv_CcaHwPartNr_SetRamBlockStatus: start-on-event=SetRamBlockStatus, operation=PSProxy_Rte_NvmBlock_CmnMfgSrv_CcaHwPartNr.SetRamBlockStatus
        OIT_SetRamBlockStatus_PSProxy_Rte_NvmBlock_CmnMfgSrv_CcaSerlNr_SetRamBlockStatus: start-on-event=SetRamBlockStatus, operation=PSProxy_Rte_NvmBlock_CmnMfgSrv_CcaSerlNr.SetRamBlockStatus
        OIT_SetRamBlockStatus_PSProxy_Rte_NvmBlock_CmnMfgSrv_DiRestore_SetRamBlockStatus: start-on-event=SetRamBlockStatus, operation=PSProxy_Rte_NvmBlock_CmnMfgSrv_DiRestore.SetRamBlockStatus
        OIT_SetRamBlockStatus_PSProxy_Rte_NvmBlock_CmnMfgSrv_EpsSysSerlNr_SetRamBlockStatus: start-on-event=SetRamBlockStatus, operation=PSProxy_Rte_NvmBlock_CmnMfgSrv_EpsSysSerlNr.SetRamBlockStatus
        OIT_SetRamBlockStatus_PSProxy_Rte_NvmBlock_CmnMfgSrv_IgnCntr_SetRamBlockStatus: start-on-event=SetRamBlockStatus, operation=PSProxy_Rte_NvmBlock_CmnMfgSrv_IgnCntr.SetRamBlockStatus
        OIT_SetRamBlockStatus_PSProxy_Rte_NvmBlock_CmnMfgSrv_MfgTmpBuf{0..4}_SetRamBlockStatus: start-on-event=SetRamBlockStatus, operation=PSProxy_Rte_NvmBlock_CmnMfgSrv_MfgTmpBuf{0..4}.SetRamBlockStatus
        OIT_SetRamBlockStatus_PSProxy_Rte_NvmBlock_CmnMfgSrv_NxtrMfgEnaCntr_SetRamBlockStatus: start-on-event=SetRamBlockStatus, operation=PSProxy_Rte_NvmBlock_CmnMfgSrv_NxtrMfgEnaCntr.SetRamBlockStatus
        OIT_SetRamBlockStatus_PSProxy_Rte_NvmBlock_CmnMfgSrv_SeedKey_SetRamBlockStatus: start-on-event=SetRamBlockStatus, operation=PSProxy_Rte_NvmBlock_CmnMfgSrv_SeedKey.SetRamBlockStatus
        OIT_SetRamBlockStatus_PSProxy_Rte_NvmBlock_DiagcMgr_DiagcMgrApplCrc_SetRamBlockStatus: start-on-event=SetRamBlockStatus, operation=PSProxy_Rte_NvmBlock_DiagcMgr_DiagcMgrApplCrc.SetRamBlockStatus
        OIT_SetRamBlockStatus_PSProxy_Rte_NvmBlock_DiagcMgr_DiagcMgrLtchCntrAry_SetRamBlockStatus: start-on-event=SetRamBlockStatus, operation=PSProxy_Rte_NvmBlock_DiagcMgr_DiagcMgrLtchCntrAry.SetRamBlockStatus
        OIT_SetRamBlockStatus_PSProxy_Rte_NvmBlock_DiagcMgr_DiagcMgrNtcFltAry_SetRamBlockStatus: start-on-event=SetRamBlockStatus, operation=PSProxy_Rte_NvmBlock_DiagcMgr_DiagcMgrNtcFltAry.SetRamBlockStatus
        OIT_SetRamBlockStatus_PSProxy_Rte_NvmBlock_HwTqCorrln_HwTqChACmnModCmpLpFilSt_SetRamBlockStatus: start-on-event=SetRamBlockStatus, operation=PSProxy_Rte_NvmBlock_HwTqCorrln_HwTqChACmnModCmpLpFilSt.SetRamBlockStatus
        OIT_SetRamBlockStatus_PSProxy_Rte_NvmBlock_PolarityCfg_PolarityCfgSaved_SetRamBlockStatus: start-on-event=SetRamBlockStatus, operation=PSProxy_Rte_NvmBlock_PolarityCfg_PolarityCfgSaved.SetRamBlockStatus
        OIT_WriteBlock_PSProxy_Rte_NvmBlock_CDD_HwTq4Meas_HwTq4Offs_MirrorBlock_WriteBlock: start-on-event=WriteBlock, operation=PSProxy_Rte_NvmBlock_CDD_HwTq4Meas_HwTq4Offs_MirrorBlock.WriteBlock
        OIT_WriteBlock_PSProxy_Rte_NvmBlock_CDD_HwTq4Meas_HwTq4Sca_MirrorBlock_WriteBlock: start-on-event=WriteBlock, operation=PSProxy_Rte_NvmBlock_CDD_HwTq4Meas_HwTq4Sca_MirrorBlock.WriteBlock
        OIT_WriteBlock_PSProxy_Rte_NvmBlock_CDD_HwTq5Meas_HwTq5Offs_MirrorBlock_WriteBlock: start-on-event=WriteBlock, operation=PSProxy_Rte_NvmBlock_CDD_HwTq5Meas_HwTq5Offs_MirrorBlock.WriteBlock
        OIT_WriteBlock_PSProxy_Rte_NvmBlock_CDD_HwTq5Meas_HwTq5Sca_MirrorBlock_WriteBlock: start-on-event=WriteBlock, operation=PSProxy_Rte_NvmBlock_CDD_HwTq5Meas_HwTq5Sca_MirrorBlock.WriteBlock
        OIT_WriteBlock_PSProxy_Rte_NvmBlock_CDD_MotAg0Meas_MotAg0CoeffTbl_WriteBlock: start-on-event=WriteBlock, operation=PSProxy_Rte_NvmBlock_CDD_MotAg0Meas_MotAg0CoeffTbl.WriteBlock
        OIT_WriteBlock_PSProxy_Rte_NvmBlock_CDD_MotAg1Meas_MotAg1CoeffTbl_WriteBlock: start-on-event=WriteBlock, operation=PSProxy_Rte_NvmBlock_CDD_MotAg1Meas_MotAg1CoeffTbl.WriteBlock
        OIT_WriteBlock_PSProxy_Rte_NvmBlock_CDD_MotAgCmp_MotAgCmpMotAgBackEmf_WriteBlock: start-on-event=WriteBlock, operation=PSProxy_Rte_NvmBlock_CDD_MotAgCmp_MotAgCmpMotAgBackEmf.WriteBlock
        OIT_WriteBlock_PSProxy_Rte_NvmBlock_CDD_NvMProxy_ShtdwnClsChk_WriteBlock: start-on-event=WriteBlock, operation=PSProxy_Rte_NvmBlock_CDD_NvMProxy_ShtdwnClsChk.WriteBlock
        OIT_WriteBlock_PSProxy_Rte_NvmBlock_CmnMfgSrv_CcaHwPartNr_WriteBlock: start-on-event=WriteBlock, operation=PSProxy_Rte_NvmBlock_CmnMfgSrv_CcaHwPartNr.WriteBlock
        OIT_WriteBlock_PSProxy_Rte_NvmBlock_CmnMfgSrv_CcaSerlNr_WriteBlock: start-on-event=WriteBlock, operation=PSProxy_Rte_NvmBlock_CmnMfgSrv_CcaSerlNr.WriteBlock
        OIT_WriteBlock_PSProxy_Rte_NvmBlock_CmnMfgSrv_DiRestore_WriteBlock: start-on-event=WriteBlock, operation=PSProxy_Rte_NvmBlock_CmnMfgSrv_DiRestore.WriteBlock
        OIT_WriteBlock_PSProxy_Rte_NvmBlock_CmnMfgSrv_EpsSysSerlNr_WriteBlock: start-on-event=WriteBlock, operation=PSProxy_Rte_NvmBlock_CmnMfgSrv_EpsSysSerlNr.WriteBlock
        OIT_WriteBlock_PSProxy_Rte_NvmBlock_CmnMfgSrv_IgnCntr_WriteBlock: start-on-event=WriteBlock, operation=PSProxy_Rte_NvmBlock_CmnMfgSrv_IgnCntr.WriteBlock
        OIT_WriteBlock_PSProxy_Rte_NvmBlock_CmnMfgSrv_MfgTmpBuf{0..4}_WriteBlock: start-on-event=WriteBlock, operation=PSProxy_Rte_NvmBlock_CmnMfgSrv_MfgTmpBuf{0..4}.WriteBlock
        OIT_WriteBlock_PSProxy_Rte_NvmBlock_CmnMfgSrv_NxtrMfgEnaCntr_WriteBlock: start-on-event=WriteBlock, operation=PSProxy_Rte_NvmBlock_CmnMfgSrv_NxtrMfgEnaCntr.WriteBlock
        OIT_WriteBlock_PSProxy_Rte_NvmBlock_CmnMfgSrv_SeedKey_WriteBlock: start-on-event=WriteBlock, operation=PSProxy_Rte_NvmBlock_CmnMfgSrv_SeedKey.WriteBlock
        OIT_WriteBlock_PSProxy_Rte_NvmBlock_DiagcMgr_DiagcMgrApplCrc_WriteBlock: start-on-event=WriteBlock, operation=PSProxy_Rte_NvmBlock_DiagcMgr_DiagcMgrApplCrc.WriteBlock
        OIT_WriteBlock_PSProxy_Rte_NvmBlock_DiagcMgr_DiagcMgrLtchCntrAry_WriteBlock: start-on-event=WriteBlock, operation=PSProxy_Rte_NvmBlock_DiagcMgr_DiagcMgrLtchCntrAry.WriteBlock
        OIT_WriteBlock_PSProxy_Rte_NvmBlock_DiagcMgr_DiagcMgrNtcFltAry_WriteBlock: start-on-event=WriteBlock, operation=PSProxy_Rte_NvmBlock_DiagcMgr_DiagcMgrNtcFltAry.WriteBlock
        OIT_WriteBlock_PSProxy_Rte_NvmBlock_HwTqCorrln_HwTqChACmnModCmpLpFilSt_WriteBlock: start-on-event=WriteBlock, operation=PSProxy_Rte_NvmBlock_HwTqCorrln_HwTqChACmnModCmpLpFilSt.WriteBlock
        OIT_WriteBlock_PSProxy_Rte_NvmBlock_PolarityCfg_PolarityCfgSaved_WriteBlock: start-on-event=WriteBlock, operation=PSProxy_Rte_NvmBlock_PolarityCfg_PolarityCfgSaved.WriteBlock
      port-api-options:
        {enable-take-address=true, error-handling=NO-TRANSFORMER-ERROR-HANDLING, indirect-api=false, port-defined-argument-value{value=PAdminProxy_Rte_NvmBlock_CDD_HwTq4Meas_HwTq4Offs_MirrorBlock_0:7, value-type=NvM_BlockIdType}, port=PAdminProxy_Rte_NvmBlock_CDD_HwTq4Meas_HwTq4Offs_MirrorBlock}
        {enable-take-address=true, error-handling=NO-TRANSFORMER-ERROR-HANDLING, indirect-api=false, port-defined-argument-value{value=PAdminProxy_Rte_NvmBlock_CDD_HwTq4Meas_HwTq4Sca_MirrorBlock_0:5, value-type=NvM_BlockIdType}, port=PAdminProxy_Rte_NvmBlock_CDD_HwTq4Meas_HwTq4Sca_MirrorBlock}
        {enable-take-address=true, error-handling=NO-TRANSFORMER-ERROR-HANDLING, indirect-api=false, port-defined-argument-value{value=PAdminProxy_Rte_NvmBlock_CDD_HwTq5Meas_HwTq5Offs_MirrorBlock_0:6, value-type=NvM_BlockIdType}, port=PAdminProxy_Rte_NvmBlock_CDD_HwTq5Meas_HwTq5Offs_MirrorBlock}
        {enable-take-address=true, error-handling=NO-TRANSFORMER-ERROR-HANDLING, indirect-api=false, port-defined-argument-value{value=PAdminProxy_Rte_NvmBlock_CDD_HwTq5Meas_HwTq5Sca_MirrorBlock_0:4, value-type=NvM_BlockIdType}, port=PAdminProxy_Rte_NvmBlock_CDD_HwTq5Meas_HwTq5Sca_MirrorBlock}
        {enable-take-address=true, error-handling=NO-TRANSFORMER-ERROR-HANDLING, indirect-api=false, port-defined-argument-value{value=PAdminProxy_Rte_NvmBlock_CDD_MotAg0Meas_MotAg0CoeffTbl_0:26, value-type=NvM_BlockIdType}, port=PAdminProxy_Rte_NvmBlock_CDD_MotAg0Meas_MotAg0CoeffTbl}
        {enable-take-address=true, error-handling=NO-TRANSFORMER-ERROR-HANDLING, indirect-api=false, port-defined-argument-value{value=PAdminProxy_Rte_NvmBlock_CDD_MotAg1Meas_MotAg1CoeffTbl_0:25, value-type=NvM_BlockIdType}, port=PAdminProxy_Rte_NvmBlock_CDD_MotAg1Meas_MotAg1CoeffTbl}
        {enable-take-address=true, error-handling=NO-TRANSFORMER-ERROR-HANDLING, indirect-api=false, port-defined-argument-value{value=PAdminProxy_Rte_NvmBlock_CDD_MotAgCmp_MotAgCmpMotAgBackEmf_0:8, value-type=NvM_BlockIdType}, port=PAdminProxy_Rte_NvmBlock_CDD_MotAgCmp_MotAgCmpMotAgBackEmf}
        {enable-take-address=true, error-handling=NO-TRANSFORMER-ERROR-HANDLING, indirect-api=false, port-defined-argument-value{value=PAdminProxy_Rte_NvmBlock_CDD_NvMProxy_ShtdwnClsChk_0:30, value-type=NvM_BlockIdType}, port=PAdminProxy_Rte_NvmBlock_CDD_NvMProxy_ShtdwnClsChk}
        {enable-take-address=true, error-handling=NO-TRANSFORMER-ERROR-HANDLING, indirect-api=false, port-defined-argument-value{value=PAdminProxy_Rte_NvmBlock_CmnMfgSrv_CcaHwPartNr_0:21, value-type=NvM_BlockIdType}, port=PAdminProxy_Rte_NvmBlock_CmnMfgSrv_CcaHwPartNr}
        {enable-take-address=true, error-handling=NO-TRANSFORMER-ERROR-HANDLING, indirect-api=false, port-defined-argument-value{value=PAdminProxy_Rte_NvmBlock_CmnMfgSrv_CcaSerlNr_0:20, value-type=NvM_BlockIdType}, port=PAdminProxy_Rte_NvmBlock_CmnMfgSrv_CcaSerlNr}
        {enable-take-address=true, error-handling=NO-TRANSFORMER-ERROR-HANDLING, indirect-api=false, port-defined-argument-value{value=PAdminProxy_Rte_NvmBlock_CmnMfgSrv_DiRestore_0:19, value-type=NvM_BlockIdType}, port=PAdminProxy_Rte_NvmBlock_CmnMfgSrv_DiRestore}
        {enable-take-address=true, error-handling=NO-TRANSFORMER-ERROR-HANDLING, indirect-api=false, port-defined-argument-value{value=PAdminProxy_Rte_NvmBlock_CmnMfgSrv_EpsSysSerlNr_0:18, value-type=NvM_BlockIdType}, port=PAdminProxy_Rte_NvmBlock_CmnMfgSrv_EpsSysSerlNr}
        {enable-take-address=true, error-handling=NO-TRANSFORMER-ERROR-HANDLING, indirect-api=false, port-defined-argument-value{value=PAdminProxy_Rte_NvmBlock_CmnMfgSrv_IgnCntr_0:17, value-type=NvM_BlockIdType}, port=PAdminProxy_Rte_NvmBlock_CmnMfgSrv_IgnCntr}
        {enable-take-address=true, error-handling=NO-TRANSFORMER-ERROR-HANDLING, indirect-api=false, port-defined-argument-value{value=PAdminProxy_Rte_NvmBlock_CmnMfgSrv_MfgTmpBuf0_0:15, value-type=NvM_BlockIdType}, port=PAdminProxy_Rte_NvmBlock_CmnMfgSrv_MfgTmpBuf0}
        {enable-take-address=true, error-handling=NO-TRANSFORMER-ERROR-HANDLING, indirect-api=false, port-defined-argument-value{value=PAdminProxy_Rte_NvmBlock_CmnMfgSrv_MfgTmpBuf1_0:14, value-type=NvM_BlockIdType}, port=PAdminProxy_Rte_NvmBlock_CmnMfgSrv_MfgTmpBuf1}
        {enable-take-address=true, error-handling=NO-TRANSFORMER-ERROR-HANDLING, indirect-api=false, port-defined-argument-value{value=PAdminProxy_Rte_NvmBlock_CmnMfgSrv_MfgTmpBuf2_0:13, value-type=NvM_BlockIdType}, port=PAdminProxy_Rte_NvmBlock_CmnMfgSrv_MfgTmpBuf2}
        {enable-take-address=true, error-handling=NO-TRANSFORMER-ERROR-HANDLING, indirect-api=false, port-defined-argument-value{value=PAdminProxy_Rte_NvmBlock_CmnMfgSrv_MfgTmpBuf3_0:12, value-type=NvM_BlockIdType}, port=PAdminProxy_Rte_NvmBlock_CmnMfgSrv_MfgTmpBuf3}
        {enable-take-address=true, error-handling=NO-TRANSFORMER-ERROR-HANDLING, indirect-api=false, port-defined-argument-value{value=PAdminProxy_Rte_NvmBlock_CmnMfgSrv_MfgTmpBuf4_0:11, value-type=NvM_BlockIdType}, port=PAdminProxy_Rte_NvmBlock_CmnMfgSrv_MfgTmpBuf4}
        {enable-take-address=true, error-handling=NO-TRANSFORMER-ERROR-HANDLING, indirect-api=false, port-defined-argument-value{value=PAdminProxy_Rte_NvmBlock_CmnMfgSrv_NxtrMfgEnaCntr_0:16, value-type=NvM_BlockIdType}, port=PAdminProxy_Rte_NvmBlock_CmnMfgSrv_NxtrMfgEnaCntr}
        {enable-take-address=true, error-handling=NO-TRANSFORMER-ERROR-HANDLING, indirect-api=false, port-defined-argument-value{value=PAdminProxy_Rte_NvmBlock_CmnMfgSrv_SeedKey_0:10, value-type=NvM_BlockIdType}, port=PAdminProxy_Rte_NvmBlock_CmnMfgSrv_SeedKey}
        {enable-take-address=true, error-handling=NO-TRANSFORMER-ERROR-HANDLING, indirect-api=false, port-defined-argument-value{value=PAdminProxy_Rte_NvmBlock_DiagcMgr_DiagcMgrApplCrc_0:27, value-type=NvM_BlockIdType}, port=PAdminProxy_Rte_NvmBlock_DiagcMgr_DiagcMgrApplCrc}
        {enable-take-address=true, error-handling=NO-TRANSFORMER-ERROR-HANDLING, indirect-api=false, port-defined-argument-value{value=PAdminProxy_Rte_NvmBlock_DiagcMgr_DiagcMgrLtchCntrAry_0:29, value-type=NvM_BlockIdType}, port=PAdminProxy_Rte_NvmBlock_DiagcMgr_DiagcMgrLtchCntrAry}
        {enable-take-address=true, error-handling=NO-TRANSFORMER-ERROR-HANDLING, indirect-api=false, port-defined-argument-value{value=PAdminProxy_Rte_NvmBlock_DiagcMgr_DiagcMgrNtcFltAry_0:28, value-type=NvM_BlockIdType}, port=PAdminProxy_Rte_NvmBlock_DiagcMgr_DiagcMgrNtcFltAry}
        {enable-take-address=true, error-handling=NO-TRANSFORMER-ERROR-HANDLING, indirect-api=false, port-defined-argument-value{value=PAdminProxy_Rte_NvmBlock_HwTqCorrln_HwTqChACmnModCmpLpFilSt_0:3, value-type=NvM_BlockIdType}, port=PAdminProxy_Rte_NvmBlock_HwTqCorrln_HwTqChACmnModCmpLpFilSt}
        {enable-take-address=true, error-handling=NO-TRANSFORMER-ERROR-HANDLING, indirect-api=false, port-defined-argument-value{value=PAdminProxy_Rte_NvmBlock_PolarityCfg_PolarityCfgSaved_0:9, value-type=NvM_BlockIdType}, port=PAdminProxy_Rte_NvmBlock_PolarityCfg_PolarityCfgSaved}
        {enable-take-address=false, error-handling=NO-TRANSFORMER-ERROR-HANDLING, indirect-api=false, port-defined-argument-value{value=PSProxy_Rte_NvmBlock_CDD_HwTq4Meas_HwTq4Offs_MirrorBlock_0:7, value-type=NvM_BlockIdType}, port=PSProxy_Rte_NvmBlock_CDD_HwTq4Meas_HwTq4Offs_MirrorBlock}
        {enable-take-address=false, error-handling=NO-TRANSFORMER-ERROR-HANDLING, indirect-api=false, port-defined-argument-value{value=PSProxy_Rte_NvmBlock_CDD_HwTq4Meas_HwTq4Sca_MirrorBlock_0:5, value-type=NvM_BlockIdType}, port=PSProxy_Rte_NvmBlock_CDD_HwTq4Meas_HwTq4Sca_MirrorBlock}
        {enable-take-address=false, error-handling=NO-TRANSFORMER-ERROR-HANDLING, indirect-api=false, port-defined-argument-value{value=PSProxy_Rte_NvmBlock_CDD_HwTq5Meas_HwTq5Offs_MirrorBlock_0:6, value-type=NvM_BlockIdType}, port=PSProxy_Rte_NvmBlock_CDD_HwTq5Meas_HwTq5Offs_MirrorBlock}
        {enable-take-address=false, error-handling=NO-TRANSFORMER-ERROR-HANDLING, indirect-api=false, port-defined-argument-value{value=PSProxy_Rte_NvmBlock_CDD_HwTq5Meas_HwTq5Sca_MirrorBlock_0:4, value-type=NvM_BlockIdType}, port=PSProxy_Rte_NvmBlock_CDD_HwTq5Meas_HwTq5Sca_MirrorBlock}
        {enable-take-address=false, error-handling=NO-TRANSFORMER-ERROR-HANDLING, indirect-api=false, port-defined-argument-value{value=PSProxy_Rte_NvmBlock_CDD_MotAg0Meas_MotAg0CoeffTbl_0:26, value-type=NvM_BlockIdType}, port=PSProxy_Rte_NvmBlock_CDD_MotAg0Meas_MotAg0CoeffTbl}
        {enable-take-address=false, error-handling=NO-TRANSFORMER-ERROR-HANDLING, indirect-api=false, port-defined-argument-value{value=PSProxy_Rte_NvmBlock_CDD_MotAg1Meas_MotAg1CoeffTbl_0:25, value-type=NvM_BlockIdType}, port=PSProxy_Rte_NvmBlock_CDD_MotAg1Meas_MotAg1CoeffTbl}
        {enable-take-address=false, error-handling=NO-TRANSFORMER-ERROR-HANDLING, indirect-api=false, port-defined-argument-value{value=PSProxy_Rte_NvmBlock_CDD_MotAgCmp_MotAgCmpMotAgBackEmf_0:8, value-type=NvM_BlockIdType}, port=PSProxy_Rte_NvmBlock_CDD_MotAgCmp_MotAgCmpMotAgBackEmf}
        {enable-take-address=false, error-handling=NO-TRANSFORMER-ERROR-HANDLING, indirect-api=false, port-defined-argument-value{value=PSProxy_Rte_NvmBlock_CDD_NvMProxy_ShtdwnClsChk_0:30, value-type=NvM_BlockIdType}, port=PSProxy_Rte_NvmBlock_CDD_NvMProxy_ShtdwnClsChk}
        {enable-take-address=false, error-handling=NO-TRANSFORMER-ERROR-HANDLING, indirect-api=false, port-defined-argument-value{value=PSProxy_Rte_NvmBlock_CmnMfgSrv_CcaHwPartNr_0:21, value-type=NvM_BlockIdType}, port=PSProxy_Rte_NvmBlock_CmnMfgSrv_CcaHwPartNr}
        {enable-take-address=false, error-handling=NO-TRANSFORMER-ERROR-HANDLING, indirect-api=false, port-defined-argument-value{value=PSProxy_Rte_NvmBlock_CmnMfgSrv_CcaSerlNr_0:20, value-type=NvM_BlockIdType}, port=PSProxy_Rte_NvmBlock_CmnMfgSrv_CcaSerlNr}
        {enable-take-address=false, error-handling=NO-TRANSFORMER-ERROR-HANDLING, indirect-api=false, port-defined-argument-value{value=PSProxy_Rte_NvmBlock_CmnMfgSrv_DiRestore_0:19, value-type=NvM_BlockIdType}, port=PSProxy_Rte_NvmBlock_CmnMfgSrv_DiRestore}
        {enable-take-address=false, error-handling=NO-TRANSFORMER-ERROR-HANDLING, indirect-api=false, port-defined-argument-value{value=PSProxy_Rte_NvmBlock_CmnMfgSrv_EpsSysSerlNr_0:18, value-type=NvM_BlockIdType}, port=PSProxy_Rte_NvmBlock_CmnMfgSrv_EpsSysSerlNr}
        {enable-take-address=false, error-handling=NO-TRANSFORMER-ERROR-HANDLING, indirect-api=false, port-defined-argument-value{value=PSProxy_Rte_NvmBlock_CmnMfgSrv_IgnCntr_0:17, value-type=NvM_BlockIdType}, port=PSProxy_Rte_NvmBlock_CmnMfgSrv_IgnCntr}
        {enable-take-address=false, error-handling=NO-TRANSFORMER-ERROR-HANDLING, indirect-api=false, port-defined-argument-value{value=PSProxy_Rte_NvmBlock_CmnMfgSrv_MfgTmpBuf0_0:15, value-type=NvM_BlockIdType}, port=PSProxy_Rte_NvmBlock_CmnMfgSrv_MfgTmpBuf0}
        {enable-take-address=false, error-handling=NO-TRANSFORMER-ERROR-HANDLING, indirect-api=false, port-defined-argument-value{value=PSProxy_Rte_NvmBlock_CmnMfgSrv_MfgTmpBuf1_0:14, value-type=NvM_BlockIdType}, port=PSProxy_Rte_NvmBlock_CmnMfgSrv_MfgTmpBuf1}
        {enable-take-address=false, error-handling=NO-TRANSFORMER-ERROR-HANDLING, indirect-api=false, port-defined-argument-value{value=PSProxy_Rte_NvmBlock_CmnMfgSrv_MfgTmpBuf2_0:13, value-type=NvM_BlockIdType}, port=PSProxy_Rte_NvmBlock_CmnMfgSrv_MfgTmpBuf2}
        {enable-take-address=false, error-handling=NO-TRANSFORMER-ERROR-HANDLING, indirect-api=false, port-defined-argument-value{value=PSProxy_Rte_NvmBlock_CmnMfgSrv_MfgTmpBuf3_0:12, value-type=NvM_BlockIdType}, port=PSProxy_Rte_NvmBlock_CmnMfgSrv_MfgTmpBuf3}
        {enable-take-address=false, error-handling=NO-TRANSFORMER-ERROR-HANDLING, indirect-api=false, port-defined-argument-value{value=PSProxy_Rte_NvmBlock_CmnMfgSrv_MfgTmpBuf4_0:11, value-type=NvM_BlockIdType}, port=PSProxy_Rte_NvmBlock_CmnMfgSrv_MfgTmpBuf4}
        {enable-take-address=false, error-handling=NO-TRANSFORMER-ERROR-HANDLING, indirect-api=false, port-defined-argument-value{value=PSProxy_Rte_NvmBlock_CmnMfgSrv_NxtrMfgEnaCntr_0:16, value-type=NvM_BlockIdType}, port=PSProxy_Rte_NvmBlock_CmnMfgSrv_NxtrMfgEnaCntr}
        {enable-take-address=false, error-handling=NO-TRANSFORMER-ERROR-HANDLING, indirect-api=false, port-defined-argument-value{value=PSProxy_Rte_NvmBlock_CmnMfgSrv_SeedKey_0:10, value-type=NvM_BlockIdType}, port=PSProxy_Rte_NvmBlock_CmnMfgSrv_SeedKey}
        {enable-take-address=false, error-handling=NO-TRANSFORMER-ERROR-HANDLING, indirect-api=false, port-defined-argument-value{value=PSProxy_Rte_NvmBlock_DiagcMgr_DiagcMgrApplCrc_0:27, value-type=NvM_BlockIdType}, port=PSProxy_Rte_NvmBlock_DiagcMgr_DiagcMgrApplCrc}
        {enable-take-address=false, error-handling=NO-TRANSFORMER-ERROR-HANDLING, indirect-api=false, port-defined-argument-value{value=PSProxy_Rte_NvmBlock_DiagcMgr_DiagcMgrLtchCntrAry_0:29, value-type=NvM_BlockIdType}, port=PSProxy_Rte_NvmBlock_DiagcMgr_DiagcMgrLtchCntrAry}
        {enable-take-address=false, error-handling=NO-TRANSFORMER-ERROR-HANDLING, indirect-api=false, port-defined-argument-value{value=PSProxy_Rte_NvmBlock_DiagcMgr_DiagcMgrNtcFltAry_0:28, value-type=NvM_BlockIdType}, port=PSProxy_Rte_NvmBlock_DiagcMgr_DiagcMgrNtcFltAry}
        {enable-take-address=false, error-handling=NO-TRANSFORMER-ERROR-HANDLING, indirect-api=false, port-defined-argument-value{value=PSProxy_Rte_NvmBlock_HwTqCorrln_HwTqChACmnModCmpLpFilSt_0:3, value-type=NvM_BlockIdType}, port=PSProxy_Rte_NvmBlock_HwTqCorrln_HwTqChACmnModCmpLpFilSt}
        {enable-take-address=false, error-handling=NO-TRANSFORMER-ERROR-HANDLING, indirect-api=false, port-defined-argument-value{value=PSProxy_Rte_NvmBlock_PolarityCfg_PolarityCfgSaved_0:9, value-type=NvM_BlockIdType}, port=PSProxy_Rte_NvmBlock_PolarityCfg_PolarityCfgSaved}
      11 x runnable:
        EraseBlock: can-be-invoked-concurrently=true, symbol=NvMProxy_EraseNvBlock
        GetDataIndex: can-be-invoked-concurrently=true, symbol=NvMProxy_GetDataIndex
        GetErrorStatus: can-be-invoked-concurrently=true, symbol=NvMProxy_GetErrorStatus
        InvalidateNvBlock: can-be-invoked-concurrently=true, symbol=NvMProxy_InvalidateNvBlock
        NvMProxy_MainFunction
        ReadBlock: can-be-invoked-concurrently=true, symbol=NvMProxy_ReadBlock
        RestoreBlockDefaults: can-be-invoked-concurrently=true, symbol=NvMProxy_RestoreBlockDefaults
        SetBlockProtection: can-be-invoked-concurrently=true, symbol=NvMProxy_SetBlockProtection
        SetDataIndex: symbol=NvM_SetDataIndex
        SetRamBlockStatus: can-be-invoked-concurrently=true, symbol=NvMProxy_SetRamBlockStatus
        WriteBlock: can-be-invoked-concurrently=true, symbol=NvMProxy_WriteBlock
  swc implementation NvMProxyImplementation: behavior=NvMProxyInternalBehavior
    code-descriptors:
      code Default: artifact-descriptors=autosar-engineering-object={short-label=Default, category=SWSRC}
